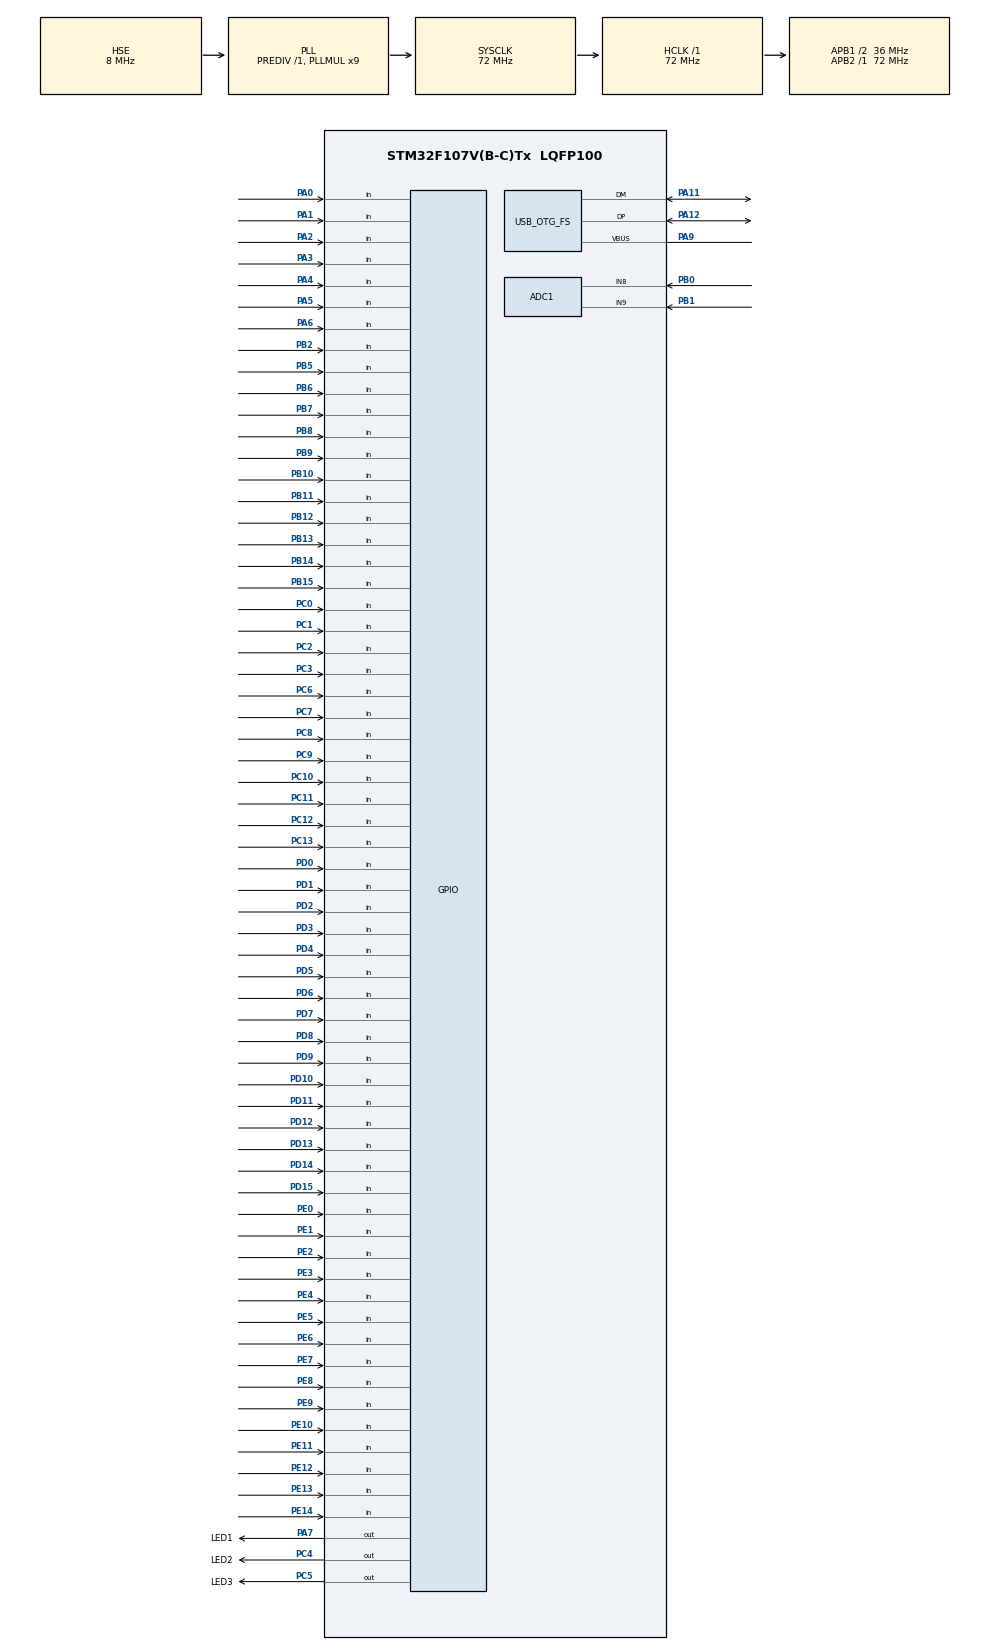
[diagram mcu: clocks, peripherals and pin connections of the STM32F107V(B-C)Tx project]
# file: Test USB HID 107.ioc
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ADC1.Channel-0\#ChannelRegularConversion=ADC_CHANNEL_8
ADC1.Channel-1\#ChannelRegularConversion=ADC_CHANNEL_9
ADC1.ContinuousConvMode=ENABLE
ADC1.NbrOfConversion=2
ADC1.NbrOfConversionFlag=1
ADC1.Rank-0\#ChannelRegularConversion=1
ADC1.Rank-1\#ChannelRegularConversion=2
ADC1.SamplingTime-0\#ChannelRegularConversion=ADC_SAMPLETIME_1CYCLE_5
ADC1.SamplingTime-1\#ChannelRegularConversion=ADC_SAMPLETIME_1CYCLE_5
ADC1.master=1
Mcu.Family=STM32F1
Mcu.Name=STM32F107V(B-C)Tx
Mcu.Package=LQFP100
NVIC.OTG_FS_IRQn=true\:0\:0\:false\:false\:true
NVIC.PriorityGroup=NVIC_PRIORITYGROUP_4
OSC_IN.Mode=HSE-External-Oscillator
OSC_IN.Signal=RCC_OSC_IN
OSC_OUT.Mode=HSE-External-Oscillator
OSC_OUT.Signal=RCC_OSC_OUT
PA0-WKUP.GPIO_Mode=GPIO_MODE_INPUT
PA0-WKUP.GPIO_PuPd=GPIO_PULLUP
PA0-WKUP.Signal=GPIO_Input
PA1.GPIO_PuPd=GPIO_PULLUP
PA1.Signal=GPIO_Input
PA11.Mode=Device_Only
PA11.Signal=USB_OTG_FS_DM
PA12.Mode=Device_Only
PA12.Signal=USB_OTG_FS_DP
PA2.GPIO_Mode=GPIO_MODE_INPUT
PA2.GPIO_PuPd=GPIO_PULLUP
PA2.Signal=GPIO_Input
PA3.GPIO_Mode=GPIO_MODE_INPUT
PA3.GPIO_PuPd=GPIO_PULLUP
PA3.Signal=GPIO_Input
PA4.GPIO_Mode=GPIO_MODE_INPUT
PA4.GPIO_PuPd=GPIO_PULLUP
PA4.Signal=GPIO_Input
PA5.GPIO_Mode=GPIO_MODE_INPUT
PA5.GPIO_PuPd=GPIO_PULLUP
PA5.Signal=GPIO_Input
PA6.GPIO_Mode=GPIO_MODE_INPUT
PA6.GPIO_PuPd=GPIO_PULLUP
PA6.Signal=GPIO_Input
PA7.GPIO_Label=LED1
PA7.GPIO_ModeDefaultOutputPP=GPIO_MODE_OUTPUT_PP
PA7.GPIO_Speed=GPIO_SPEED_FREQ_HIGH
PA7.PinState=GPIO_PIN_RESET
PA7.Signal=GPIO_Output
PA9.Mode=Activate_VBUS
PA9.Signal=USB_OTG_FS_VBUS
PB0.Signal=ADCx_IN8
PB1.Signal=ADCx_IN9
PB10.GPIO_Mode=GPIO_MODE_INPUT
PB10.GPIO_PuPd=GPIO_PULLUP
PB10.Signal=GPIO_Input
PB11.GPIO_Mode=GPIO_MODE_INPUT
PB11.GPIO_PuPd=GPIO_PULLUP
PB11.Signal=GPIO_Input
PB12.GPIO_Mode=GPIO_MODE_INPUT
PB12.GPIO_PuPd=GPIO_PULLUP
PB12.Signal=GPIO_Input
PB13.GPIO_Mode=GPIO_MODE_INPUT
PB13.GPIO_PuPd=GPIO_PULLUP
PB13.Signal=GPIO_Input
PB14.GPIO_Mode=GPIO_MODE_INPUT
PB14.GPIO_PuPd=GPIO_PULLUP
PB14.Signal=GPIO_Input
PB15.GPIO_Mode=GPIO_MODE_INPUT
PB15.GPIO_PuPd=GPIO_PULLUP
PB15.Signal=GPIO_Input
PB2.GPIO_Mode=GPIO_MODE_INPUT
PB2.GPIO_PuPd=GPIO_PULLUP
PB2.Signal=GPIO_Input
PB5.GPIO_Mode=GPIO_MODE_INPUT
PB5.GPIO_PuPd=GPIO_PULLUP
PB5.Signal=GPIO_Input
PB6.GPIO_Mode=GPIO_MODE_INPUT
PB6.GPIO_PuPd=GPIO_PULLUP
PB6.Signal=GPIO_Input
PB7.GPIO_Mode=GPIO_MODE_INPUT
PB7.GPIO_PuPd=GPIO_PULLUP
PB7.Signal=GPIO_Input
PB8.GPIO_Mode=GPIO_MODE_INPUT
PB8.GPIO_PuPd=GPIO_PULLUP
PB8.Signal=GPIO_Input
PB9.GPIO_Mode=GPIO_MODE_INPUT
PB9.GPIO_PuPd=GPIO_PULLUP
PB9.Signal=GPIO_Input
PC0.GPIO_Mode=GPIO_MODE_INPUT
PC0.GPIO_PuPd=GPIO_PULLUP
PC0.Signal=GPIO_Input
PC1.GPIO_Mode=GPIO_MODE_INPUT
PC1.GPIO_PuPd=GPIO_PULLUP
PC1.Signal=GPIO_Input
PC10.GPIO_Mode=GPIO_MODE_INPUT
PC10.GPIO_PuPd=GPIO_PULLUP
PC10.Signal=GPIO_Input
PC11.GPIO_Mode=GPIO_MODE_INPUT
PC11.GPIO_PuPd=GPIO_PULLUP
PC11.Signal=GPIO_Input
PC12.GPIO_Mode=GPIO_MODE_INPUT
PC12.GPIO_PuPd=GPIO_PULLUP
PC12.Signal=GPIO_Input
PC13-TAMPER-RTC.GPIO_Mode=GPIO_MODE_INPUT
PC13-TAMPER-RTC.GPIO_PuPd=GPIO_PULLUP
PC13-TAMPER-RTC.Signal=GPIO_Input
PC2.GPIO_Mode=GPIO_MODE_INPUT
PC2.GPIO_PuPd=GPIO_PULLUP
PC2.Signal=GPIO_Input
PC3.GPIO_Mode=GPIO_MODE_INPUT
PC3.GPIO_PuPd=GPIO_PULLUP
PC3.Signal=GPIO_Input
PC4.GPIO_Label=LED2
PC4.GPIO_ModeDefaultOutputPP=GPIO_MODE_OUTPUT_PP
PC4.GPIO_Speed=GPIO_SPEED_FREQ_HIGH
PC4.PinState=GPIO_PIN_RESET
PC4.Signal=GPIO_Output
PC5.GPIO_Label=LED3
PC5.GPIO_ModeDefaultOutputPP=GPIO_MODE_OUTPUT_PP
PC5.GPIO_Speed=GPIO_SPEED_FREQ_HIGH
PC5.PinState=GPIO_PIN_RESET
PC5.Signal=GPIO_Output
PC6.GPIO_Mode=GPIO_MODE_INPUT
PC6.GPIO_PuPd=GPIO_PULLUP
PC6.Signal=GPIO_Input
PC7.GPIO_Mode=GPIO_MODE_INPUT
PC7.GPIO_PuPd=GPIO_PULLUP
PC7.Signal=GPIO_Input
PC8.GPIO_Mode=GPIO_MODE_INPUT
PC8.GPIO_PuPd=GPIO_PULLUP
PC8.Signal=GPIO_Input
PC9.GPIO_Mode=GPIO_MODE_INPUT
PC9.GPIO_PuPd=GPIO_PULLUP
PC9.Signal=GPIO_Input
PD0.GPIO_Mode=GPIO_MODE_INPUT
PD0.GPIO_PuPd=GPIO_PULLUP
PD0.Signal=GPIO_Input
PD1.GPIO_Mode=GPIO_MODE_INPUT
PD1.GPIO_PuPd=GPIO_PULLUP
PD1.Signal=GPIO_Input
PD10.GPIO_Mode=GPIO_MODE_INPUT
PD10.GPIO_PuPd=GPIO_PULLUP
PD10.Signal=GPIO_Input
PD11.GPIO_Mode=GPIO_MODE_INPUT
PD11.GPIO_PuPd=GPIO_PULLUP
PD11.Signal=GPIO_Input
PD12.GPIO_Mode=GPIO_MODE_INPUT
PD12.GPIO_PuPd=GPIO_PULLUP
PD12.Signal=GPIO_Input
PD13.GPIO_Mode=GPIO_MODE_INPUT
PD13.GPIO_PuPd=GPIO_PULLUP
PD13.Signal=GPIO_Input
PD14.GPIO_Mode=GPIO_MODE_INPUT
PD14.GPIO_PuPd=GPIO_PULLUP
PD14.Signal=GPIO_Input
PD15.GPIO_PuPd=GPIO_PULLUP
PD15.Signal=GPIO_Input
PD2.GPIO_Mode=GPIO_MODE_INPUT
PD2.GPIO_PuPd=GPIO_PULLUP
PD2.Signal=GPIO_Input
PD3.GPIO_Mode=GPIO_MODE_INPUT
PD3.GPIO_PuPd=GPIO_PULLUP
PD3.Signal=GPIO_Input
PD4.GPIO_Mode=GPIO_MODE_INPUT
PD4.GPIO_PuPd=GPIO_PULLUP
PD4.Signal=GPIO_Input
PD5.GPIO_Mode=GPIO_MODE_INPUT
PD5.GPIO_PuPd=GPIO_PULLUP
PD5.Signal=GPIO_Input
PD6.GPIO_Mode=GPIO_MODE_INPUT
PD6.GPIO_PuPd=GPIO_PULLUP
PD6.Signal=GPIO_Input
PD7.GPIO_Mode=GPIO_MODE_INPUT
PD7.GPIO_PuPd=GPIO_PULLUP
PD7.Signal=GPIO_Input
PD8.GPIO_Mode=GPIO_MODE_INPUT
PD8.GPIO_PuPd=GPIO_PULLUP
PD8.Signal=GPIO_Input
PD9.GPIO_Mode=GPIO_MODE_INPUT
PD9.GPIO_PuPd=GPIO_PULLUP
PD9.Signal=GPIO_Input
PE0.GPIO_Mode=GPIO_MODE_INPUT
PE0.GPIO_PuPd=GPIO_PULLUP
PE0.Signal=GPIO_Input
PE1.GPIO_Mode=GPIO_MODE_INPUT
PE1.GPIO_PuPd=GPIO_PULLUP
PE1.Signal=GPIO_Input
PE10.GPIO_Mode=GPIO_MODE_INPUT
PE10.GPIO_PuPd=GPIO_PULLUP
PE10.Signal=GPIO_Input
PE11.GPIO_Mode=GPIO_MODE_INPUT
PE11.GPIO_PuPd=GPIO_PULLUP
PE11.Signal=GPIO_Input
PE12.GPIO_Mode=GPIO_MODE_INPUT
PE12.GPIO_PuPd=GPIO_PULLUP
PE12.Signal=GPIO_Input
PE13.GPIO_Mode=GPIO_MODE_INPUT
PE13.GPIO_PuPd=GPIO_PULLUP
PE13.Signal=GPIO_Input
PE14.GPIO_Mode=GPIO_MODE_INPUT
PE14.GPIO_PuPd=GPIO_PULLUP
PE14.Signal=GPIO_Input
PE2.GPIO_Mode=GPIO_MODE_INPUT
PE2.GPIO_PuPd=GPIO_PULLUP
PE2.Signal=GPIO_Input
PE3.GPIO_Mode=GPIO_MODE_INPUT
PE3.GPIO_PuPd=GPIO_PULLUP
PE3.Signal=GPIO_Input
PE4.GPIO_Mode=GPIO_MODE_INPUT
PE4.GPIO_PuPd=GPIO_PULLUP
PE4.Signal=GPIO_Input
PE5.GPIO_Mode=GPIO_MODE_INPUT
PE5.GPIO_PuPd=GPIO_PULLUP
PE5.Signal=GPIO_Input
PE6.Signal=GPIO_Input
PE7.GPIO_Mode=GPIO_MODE_INPUT
PE7.GPIO_PuPd=GPIO_PULLUP
PE7.Signal=GPIO_Input
PE8.GPIO_Mode=GPIO_MODE_INPUT
PE8.GPIO_PuPd=GPIO_PULLUP
PE8.Signal=GPIO_Input
PE9.GPIO_Mode=GPIO_MODE_INPUT
PE9.GPIO_PuPd=GPIO_PULLUP
PE9.Signal=GPIO_Input
ProjectManager.HeapSize=0x200
ProjectManager.StackSize=0x400
ProjectManager.TargetToolchain=MDK-ARM V5
RCC.ADCPresc=RCC_ADCPCLK2_DIV8
RCC.AHBFreq_Value=72000000
RCC.APB1CLKDivider=RCC_HCLK_DIV2
RCC.APB1Freq_Value=36000000
RCC.APB1TimFreq_Value=72000000
RCC.APB2Freq_Value=72000000
RCC.APB2TimCLKDivider=2
RCC.APB2TimFreq_Value=144000000
RCC.HCLKFreq_Value=72000000
RCC.HSIState=RCC_HSI_ON
RCC.PLLMUL=RCC_PLL_MUL9
RCC.SYSCLKFreq_VALUE=72000000
RCC.SYSCLKSource=RCC_SYSCLKSOURCE_PLLCLK
RCC.USBFreq_Value=48000000
SH.ADCx_IN8.0=ADC1_IN8,IN8
SH.ADCx_IN9.0=ADC1_IN9,IN9
USB_DEVICE.USBD_HandleTypeDef=hUsbDeviceFS
USB_DEVICE.VirtualMode=Hid
USB_DEVICE.VirtualModeFS=Hid_FS
USB_OTG_FS.VirtualMode=Device_Only
VP_SYS_VS_ND.Mode=No_Debug
VP_USB_DEVICE_VS_USB_DEVICE_HID_FS.Mode=HID_FS
board=Test USB HID 107

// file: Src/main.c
/**
  ******************************************************************************
  * File Name          : main.c
  * Description        : Main program body
  ******************************************************************************
  *
  * Copyright (c) 2016 STMicroelectronics International N.V.
  * All rights reserved.
  *
  * Redistribution and use in source and binary forms, with or without
  * modification, are permitted, provided that the following conditions are met:
  *
  * 1. Redistribution of source code must retain the above copyright notice,
  *    this list of conditions and the following disclaimer.
  * 2. Redistributions in binary form must reproduce the above copyright notice,
  *    this list of conditions and the following disclaimer in the documentation
  *    and/or other materials provided with the distribution.
  * 3. Neither the name of STMicroelectronics nor the names of other
  *    contributors to this software may be used to endorse or promote products
  *    derived from this software without specific written permission.
  * 4. This software, including modifications and/or derivative works of this
  *    software, must execute solely and exclusively on microcontroller or
  *    microprocessor devices manufactured by or for STMicroelectronics.
  * 5. Redistribution and use of this software other than as permitted under
  *    this license is void and will automatically terminate your rights under
  *    this license.
  *
  * THIS SOFTWARE IS PROVIDED BY STMICROELECTRONICS AND CONTRIBUTORS "AS IS"
  * AND ANY EXPRESS, IMPLIED OR STATUTORY WARRANTIES, INCLUDING, BUT NOT
  * LIMITED TO, THE IMPLIED WARRANTIES OF MERCHANTABILITY, FITNESS FOR A
  * PARTICULAR PURPOSE AND NON-INFRINGEMENT OF THIRD PARTY INTELLECTUAL PROPERTY
  * RIGHTS ARE DISCLAIMED TO THE FULLEST EXTENT PERMITTED BY LAW. IN NO EVENT
  * SHALL STMICROELECTRONICS OR CONTRIBUTORS BE LIABLE FOR ANY DIRECT, INDIRECT,
  * INCIDENTAL, SPECIAL, EXEMPLARY, OR CONSEQUENTIAL DAMAGES (INCLUDING, BUT NOT
  * LIMITED TO, PROCUREMENT OF SUBSTITUTE GOODS OR SERVICES; LOSS OF USE, DATA,
  * OR PROFITS; OR BUSINESS INTERRUPTION) HOWEVER CAUSED AND ON ANY THEORY OF
  * LIABILITY, WHETHER IN CONTRACT, STRICT LIABILITY, OR TORT (INCLUDING
  * NEGLIGENCE OR OTHERWISE) ARISING IN ANY WAY OUT OF THE USE OF THIS SOFTWARE,
  * EVEN IF ADVISED OF THE POSSIBILITY OF SUCH DAMAGE.
  *
  ******************************************************************************
  */
#include "main.h"
#include "stm32f1xx_hal.h"
#include "usb_device.h"

/* USER CODE BEGIN Includes */
#include "usbd_hid.h" //Add
/* USER CODE END Includes */

ADC_HandleTypeDef hadc1;
DMA_HandleTypeDef hdma_adc1;

/* USER CODE BEGIN PV */
/* Private variables ---------------------------------------------------------*/
__IO uint16_t ADC_value[2] = {0};
/* USER CODE END PV */

void SystemClock_Config(void);
void Error_Handler(void);
static void MX_GPIO_Init(void);
static void MX_DMA_Init(void);
static void MX_ADC1_Init(void);

/* USER CODE BEGIN PFP */
/* Private function prototypes -----------------------------------------------*/
extern USBD_HandleTypeDef hUsbDeviceFS;
/* USER CODE END PFP */

/* USER CODE BEGIN 0 */

/*
 * Keyboard buffer:
 * buf[1]: MOD (2=SHIFT, 1= CTRL,3=?
 * buf[2]: reserved
 * buf[3]..buf[8] - keycodes 1..6
 */

uint8_t buffer[8]= {0,0,0,0,0,0,0,0};//

void keyboard_write(uint8_t char1){
    buffer[2]=char1;
    USBD_HID_SendReport(&hUsbDeviceFS,buffer,8); //sizeof(buffer));
    HAL_Delay(100);
		buffer[0] = 0; buffer[2]=0; USBD_HID_SendReport(&hUsbDeviceFS,buffer,8);
}

void ReadKeyboard (void)
{
	//GPIOD
	if (!HAL_GPIO_ReadPin(GPIOD,GPIO_PIN_15)) { HAL_Delay(10); if (!HAL_GPIO_ReadPin(GPIOD,GPIO_PIN_15)) { while (!HAL_GPIO_ReadPin(GPIOD,GPIO_PIN_15)){} keyboard_write(KEY_J);}}	//J
	if (!HAL_GPIO_ReadPin(GPIOD,GPIO_PIN_14)) { HAL_Delay(10); if (!HAL_GPIO_ReadPin(GPIOD,GPIO_PIN_14)) { while (!HAL_GPIO_ReadPin(GPIOD,GPIO_PIN_14)){} keyboard_write(KEY_K);}}	//K
	if (!HAL_GPIO_ReadPin(GPIOD,GPIO_PIN_13)) { HAL_Delay(10); if (!HAL_GPIO_ReadPin(GPIOD,GPIO_PIN_13)) { while (!HAL_GPIO_ReadPin(GPIOD,GPIO_PIN_13)){} keyboard_write(KEY_L);}}	//L
	if (!HAL_GPIO_ReadPin(GPIOD,GPIO_PIN_12)) { HAL_Delay(10); if (!HAL_GPIO_ReadPin(GPIOD,GPIO_PIN_12)) { while (!HAL_GPIO_ReadPin(GPIOD,GPIO_PIN_12)){} keyboard_write(KEY_F8);}}		// ,
	if (!HAL_GPIO_ReadPin(GPIOD,GPIO_PIN_11)) { HAL_Delay(10); if (!HAL_GPIO_ReadPin(GPIOD,GPIO_PIN_11)) { while (!HAL_GPIO_ReadPin(GPIOD,GPIO_PIN_11)){} keyboard_write(KEY_F9);}}		// =
	if (!HAL_GPIO_ReadPin(GPIOD,GPIO_PIN_10)) { HAL_Delay(10); if (!HAL_GPIO_ReadPin(GPIOD,GPIO_PIN_10)) { while (!HAL_GPIO_ReadPin(GPIOD,GPIO_PIN_10)){} keyboard_write(KEY_F21);}}	//F11 -> F21
	if (!HAL_GPIO_ReadPin(GPIOD,GPIO_PIN_9)) { HAL_Delay(10); if (!HAL_GPIO_ReadPin(GPIOD,GPIO_PIN_9)) { while (!HAL_GPIO_ReadPin(GPIOD,GPIO_PIN_9)){} keyboard_write(KEY_F20);}}			//F10->20
	if (!HAL_GPIO_ReadPin(GPIOD,GPIO_PIN_8)) { HAL_Delay(10); if (!HAL_GPIO_ReadPin(GPIOD,GPIO_PIN_8)) { while (!HAL_GPIO_ReadPin(GPIOD,GPIO_PIN_8)){} keyboard_write(KEY_F4);}}			//^ ???
	if (!HAL_GPIO_ReadPin(GPIOD,GPIO_PIN_7)) { HAL_Delay(10); if (!HAL_GPIO_ReadPin(GPIOD,GPIO_PIN_7)) { while (!HAL_GPIO_ReadPin(GPIOD,GPIO_PIN_7)){} keyboard_write(KEY_G);}}			//G
	if (!HAL_GPIO_ReadPin(GPIOD,GPIO_PIN_6)) { HAL_Delay(10); if (!HAL_GPIO_ReadPin(GPIOD,GPIO_PIN_6)) { while (!HAL_GPIO_ReadPin(GPIOD,GPIO_PIN_6)){} keyboard_write(KEY_H);}}			//H
	if (!HAL_GPIO_ReadPin(GPIOD,GPIO_PIN_5)) { HAL_Delay(10); if (!HAL_GPIO_ReadPin(GPIOD,GPIO_PIN_5)) { while (!HAL_GPIO_ReadPin(GPIOD,GPIO_PIN_5)){} keyboard_write(KEY_U);}}			//U
	if (!HAL_GPIO_ReadPin(GPIOD,GPIO_PIN_4)) { HAL_Delay(10); if (!HAL_GPIO_ReadPin(GPIOD,GPIO_PIN_4)) { while (!HAL_GPIO_ReadPin(GPIOD,GPIO_PIN_4)){} keyboard_write(KEY_I);}}			//I
	if (!HAL_GPIO_ReadPin(GPIOD,GPIO_PIN_3)) { HAL_Delay(10); if (!HAL_GPIO_ReadPin(GPIOD,GPIO_PIN_3)) { while (!HAL_GPIO_ReadPin(GPIOD,GPIO_PIN_3)){} keyboard_write(KEY_O);}}		//O
	if (!HAL_GPIO_ReadPin(GPIOD,GPIO_PIN_2)) { HAL_Delay(10); if (!HAL_GPIO_ReadPin(GPIOD,GPIO_PIN_2)) { while (!HAL_GPIO_ReadPin(GPIOD,GPIO_PIN_2)){} keyboard_write(KEY_P);}}			//P
	if (!HAL_GPIO_ReadPin(GPIOD,GPIO_PIN_1)) { HAL_Delay(10); if (!HAL_GPIO_ReadPin(GPIOD,GPIO_PIN_1)) { while (!HAL_GPIO_ReadPin(GPIOD,GPIO_PIN_1)){} keyboard_write(KEY_F13);}}		//[
	if (!HAL_GPIO_ReadPin(GPIOD,GPIO_PIN_0)) { HAL_Delay(10); if (!HAL_GPIO_ReadPin(GPIOD,GPIO_PIN_0)) { while (!HAL_GPIO_ReadPin(GPIOD,GPIO_PIN_0)){} keyboard_write(KEY_F14);}}		//]
 // GPIOA
 	//if (!HAL_GPIO_ReadPin(GPIOA,GPIO_PIN_7)) { HAL_Delay(10); if (!HAL_GPIO_ReadPin(GPIOA,GPIO_PIN_7)) { while (!HAL_GPIO_ReadPin(GPIOA,GPIO_PIN_7)){} keyboard_write(KEY_G);}}			//LED
	if (!HAL_GPIO_ReadPin(GPIOA,GPIO_PIN_6)) { HAL_Delay(10); if (!HAL_GPIO_ReadPin(GPIOA,GPIO_PIN_6)) { while (!HAL_GPIO_ReadPin(GPIOA,GPIO_PIN_6)){} keyboard_write(KEY_X);}}			//X
	if (!HAL_GPIO_ReadPin(GPIOA,GPIO_PIN_5)) { HAL_Delay(10); if (!HAL_GPIO_ReadPin(GPIOA,GPIO_PIN_5)) { while (!HAL_GPIO_ReadPin(GPIOA,GPIO_PIN_5)){} keyboard_write(KEY_Z);}}			//Z
	if (!HAL_GPIO_ReadPin(GPIOA,GPIO_PIN_4)) { HAL_Delay(10); if (!HAL_GPIO_ReadPin(GPIOA,GPIO_PIN_4)) { while (!HAL_GPIO_ReadPin(GPIOA,GPIO_PIN_4)){} keyboard_write(KEY_HOME);}}			//"
	if (!HAL_GPIO_ReadPin(GPIOA,GPIO_PIN_3)) { HAL_Delay(10); if (!HAL_GPIO_ReadPin(GPIOA,GPIO_PIN_3)) { while (!HAL_GPIO_ReadPin(GPIOA,GPIO_PIN_3)){} keyboard_write(KEY_A);}}		//;
	if (!HAL_GPIO_ReadPin(GPIOA,GPIO_PIN_2)) { HAL_Delay(10); if (!HAL_GPIO_ReadPin(GPIOA,GPIO_PIN_2)) { while (!HAL_GPIO_ReadPin(GPIOA,GPIO_PIN_2)){} keyboard_write(KEY_BACKSPACE);}}			//<--
	if (!HAL_GPIO_ReadPin(GPIOA,GPIO_PIN_1)) { HAL_Delay(10); if (!HAL_GPIO_ReadPin(GPIOA,GPIO_PIN_1)) { while (!HAL_GPIO_ReadPin(GPIOA,GPIO_PIN_1)){} keyboard_write(KEY_KEYPAD_0_INSERT);}}		//0
	if (!HAL_GPIO_ReadPin(GPIOA,GPIO_PIN_0)) { HAL_Delay(10); if (!HAL_GPIO_ReadPin(GPIOA,GPIO_PIN_0)) { while (!HAL_GPIO_ReadPin(GPIOA,GPIO_PIN_0)){} keyboard_write(KEY_KEYPAD_9_PAGEUP);}}		//9
	//GPIOB
	if (!HAL_GPIO_ReadPin(GPIOB,GPIO_PIN_15)) { HAL_Delay(10); if (!HAL_GPIO_ReadPin(GPIOB,GPIO_PIN_15)) { while (!HAL_GPIO_ReadPin(GPIOB,GPIO_PIN_15)){} keyboard_write(KEY_F5);}}	//&
	if (!HAL_GPIO_ReadPin(GPIOB,GPIO_PIN_14)) { HAL_Delay(10); if (!HAL_GPIO_ReadPin(GPIOB,GPIO_PIN_14)) { while (!HAL_GPIO_ReadPin(GPIOB,GPIO_PIN_14)){} keyboard_write(KEY_F7);}}	//(
	if (!HAL_GPIO_ReadPin(GPIOB,GPIO_PIN_13)) { HAL_Delay(10); if (!HAL_GPIO_ReadPin(GPIOB,GPIO_PIN_13)) { while (!HAL_GPIO_ReadPin(GPIOB,GPIO_PIN_13)){} keyboard_write(KEY_F6);}}		//*
	if (!HAL_GPIO_ReadPin(GPIOB,GPIO_PIN_12)) { HAL_Delay(10); if (!HAL_GPIO_ReadPin(GPIOB,GPIO_PIN_12)) { while (!HAL_GPIO_ReadPin(GPIOB,GPIO_PIN_12)){} keyboard_write(KEY_ESCAPE);}}		//!
	if (!HAL_GPIO_ReadPin(GPIOB,GPIO_PIN_11)) { HAL_Delay(10); if (!HAL_GPIO_ReadPin(GPIOB,GPIO_PIN_11)) { while (!HAL_GPIO_ReadPin(GPIOB,GPIO_PIN_11)){} keyboard_write(KEY_F1);}}		//F1
	if (!HAL_GPIO_ReadPin(GPIOB,GPIO_PIN_10)) { HAL_Delay(10); if (!HAL_GPIO_ReadPin(GPIOB,GPIO_PIN_10)) { while (!HAL_GPIO_ReadPin(GPIOB,GPIO_PIN_10)){} keyboard_write(KEY_F2);}}		//F2
	if (!HAL_GPIO_ReadPin(GPIOB,GPIO_PIN_9)) { HAL_Delay(10); if (!HAL_GPIO_ReadPin(GPIOB,GPIO_PIN_9)) { while (!HAL_GPIO_ReadPin(GPIOB,GPIO_PIN_9)){} keyboard_write(KEY_S);}}			//S
	if (!HAL_GPIO_ReadPin(GPIOB,GPIO_PIN_8)) { HAL_Delay(10); if (!HAL_GPIO_ReadPin(GPIOB,GPIO_PIN_8)) { while (!HAL_GPIO_ReadPin(GPIOB,GPIO_PIN_8)){} keyboard_write(KEY_D);}}			//D
	if (!HAL_GPIO_ReadPin(GPIOB,GPIO_PIN_7)) { HAL_Delay(10); if (!HAL_GPIO_ReadPin(GPIOB,GPIO_PIN_7)) { while (!HAL_GPIO_ReadPin(GPIOB,GPIO_PIN_7)){} keyboard_write(KEY_F);}}			//F
	if (!HAL_GPIO_ReadPin(GPIOB,GPIO_PIN_6)) { HAL_Delay(10); if (!HAL_GPIO_ReadPin(GPIOB,GPIO_PIN_6)) { while (!HAL_GPIO_ReadPin(GPIOB,GPIO_PIN_6)){} keyboard_write(KEY_T);}}			//T
	if (!HAL_GPIO_ReadPin(GPIOB,GPIO_PIN_5)) { HAL_Delay(10); if (!HAL_GPIO_ReadPin(GPIOB,GPIO_PIN_5)) { while (!HAL_GPIO_ReadPin(GPIOB,GPIO_PIN_5)){} keyboard_write(KEY_Y);}}			//Y
				// Joytick Button ....
	if (!HAL_GPIO_ReadPin(GPIOB,GPIO_PIN_2)) { HAL_Delay(10); if (!HAL_GPIO_ReadPin(GPIOB,GPIO_PIN_2)) { while (!HAL_GPIO_ReadPin(GPIOB,GPIO_PIN_2)){} keyboard_write(KEY_ENTER);}}			//KEY_ENTER

	//GPIOC
	if (!HAL_GPIO_ReadPin(GPIOC,GPIO_PIN_14)) { HAL_Delay(10); if (!HAL_GPIO_ReadPin(GPIOC,GPIO_PIN_14)) { while (!HAL_GPIO_ReadPin(GPIOC,GPIO_PIN_14)){} keyboard_write(KEY_V);}}		//V
	if (!HAL_GPIO_ReadPin(GPIOC,GPIO_PIN_13)) { HAL_Delay(10); if (!HAL_GPIO_ReadPin(GPIOC,GPIO_PIN_13)) { while (!HAL_GPIO_ReadPin(GPIOC,GPIO_PIN_13)){} keyboard_write(KEY_KEYPAD_4_LEFT_ARROW);}}		//4
	if (!HAL_GPIO_ReadPin(GPIOC,GPIO_PIN_12)) { HAL_Delay(10); if (!HAL_GPIO_ReadPin(GPIOC,GPIO_PIN_12)) { while (!HAL_GPIO_ReadPin(GPIOC,GPIO_PIN_12)){} keyboard_write(KEY_PAGEUP);}}		//{
	if (!HAL_GPIO_ReadPin(GPIOC,GPIO_PIN_11)) { HAL_Delay(10); if (!HAL_GPIO_ReadPin(GPIOC,GPIO_PIN_11)) { while (!HAL_GPIO_ReadPin(GPIOC,GPIO_PIN_11)){} keyboard_write(KEY_PAGEDOWN);}}		//}
	if (!HAL_GPIO_ReadPin(GPIOC,GPIO_PIN_10)) { HAL_Delay(10); if (!HAL_GPIO_ReadPin(GPIOC,GPIO_PIN_10)) { while (!HAL_GPIO_ReadPin(GPIOC,GPIO_PIN_10)){} keyboard_write(KEY_LEFTARROW);}}		//LEFT
	if (!HAL_GPIO_ReadPin(GPIOC,GPIO_PIN_9)) { HAL_Delay(10); if (!HAL_GPIO_ReadPin(GPIOC,GPIO_PIN_9)) { while (!HAL_GPIO_ReadPin(GPIOC,GPIO_PIN_9)){} keyboard_write(KEY_RIGHTARROW);}}	//RIGHT
	if (!HAL_GPIO_ReadPin(GPIOC,GPIO_PIN_8)) { HAL_Delay(10); if (!HAL_GPIO_ReadPin(GPIOC,GPIO_PIN_8)) { while (!HAL_GPIO_ReadPin(GPIOC,GPIO_PIN_8)){} keyboard_write(KEY_UPARROW);}}			//UP
	if (!HAL_GPIO_ReadPin(GPIOC,GPIO_PIN_7)) { HAL_Delay(10); if (!HAL_GPIO_ReadPin(GPIOC,GPIO_PIN_7)) { while (!HAL_GPIO_ReadPin(GPIOC,GPIO_PIN_7)){} keyboard_write(KEY_DOWNARROW);}}			//DOWN
	if (!HAL_GPIO_ReadPin(GPIOC,GPIO_PIN_6)) { HAL_Delay(10); if (!HAL_GPIO_ReadPin(GPIOC,GPIO_PIN_6)) { while (!HAL_GPIO_ReadPin(GPIOC,GPIO_PIN_6)){} keyboard_write(KEY_C);}}		//C CENTER
	if (!HAL_GPIO_ReadPin(GPIOC,GPIO_PIN_3)) { HAL_Delay(10); if (!HAL_GPIO_ReadPin(GPIOC,GPIO_PIN_3)) { while (!HAL_GPIO_ReadPin(GPIOC,GPIO_PIN_3)){} keyboard_write(KEY_KEYPAD_8_UP_ARROW);}}		//8
	if (!HAL_GPIO_ReadPin(GPIOC,GPIO_PIN_2)) { HAL_Delay(10); if (!HAL_GPIO_ReadPin(GPIOC,GPIO_PIN_2)) { while (!HAL_GPIO_ReadPin(GPIOC,GPIO_PIN_2)){} keyboard_write(KEY_KEYPAD_7_HOME);}}		//7
	if (!HAL_GPIO_ReadPin(GPIOC,GPIO_PIN_1)) { HAL_Delay(10); if (!HAL_GPIO_ReadPin(GPIOC,GPIO_PIN_1)) { while (!HAL_GPIO_ReadPin(GPIOC,GPIO_PIN_1)){} keyboard_write(KEY_KEYPAD_6_RIGHT_ARROW);}}		//6
	if (!HAL_GPIO_ReadPin(GPIOC,GPIO_PIN_0)) { HAL_Delay(10); if (!HAL_GPIO_ReadPin(GPIOC,GPIO_PIN_0)) { while (!HAL_GPIO_ReadPin(GPIOC,GPIO_PIN_0)){} keyboard_write(KEY_KEYPAD_5);}}		//5
	//GPIOE
	if (!HAL_GPIO_ReadPin(GPIOE,GPIO_PIN_14)) { HAL_Delay(10); if (!HAL_GPIO_ReadPin(GPIOE,GPIO_PIN_14)) { while (!HAL_GPIO_ReadPin(GPIOE,GPIO_PIN_14)){} keyboard_write(KEY_F3);}}	 // F3
	if (!HAL_GPIO_ReadPin(GPIOE,GPIO_PIN_13)) { HAL_Delay(10); if (!HAL_GPIO_ReadPin(GPIOE,GPIO_PIN_13)) { while (!HAL_GPIO_ReadPin(GPIOE,GPIO_PIN_13)){} keyboard_write(KEY_F12 );}}		// <	,
	if (!HAL_GPIO_ReadPin(GPIOE,GPIO_PIN_12)) { HAL_Delay(10); if (!HAL_GPIO_ReadPin(GPIOE,GPIO_PIN_12)) { while (!HAL_GPIO_ReadPin(GPIOE,GPIO_PIN_12)){} keyboard_write(KEY_END1);}}		// > .
	if (!HAL_GPIO_ReadPin(GPIOE,GPIO_PIN_11)) { HAL_Delay(10); if (!HAL_GPIO_ReadPin(GPIOE,GPIO_PIN_11)) { while (!HAL_GPIO_ReadPin(GPIOE,GPIO_PIN_11)){} keyboard_write(KEY_DELETE);}}		// /
	if (!HAL_GPIO_ReadPin(GPIOE,GPIO_PIN_10)) { HAL_Delay(10); if (!HAL_GPIO_ReadPin(GPIOE,GPIO_PIN_10)) { while (!HAL_GPIO_ReadPin(GPIOE,GPIO_PIN_10)){} keyboard_write(KEY_INSERT);}}		// ? => `
	if (!HAL_GPIO_ReadPin(GPIOE,GPIO_PIN_9)) { HAL_Delay(10); if (!HAL_GPIO_ReadPin(GPIOE,GPIO_PIN_9)) { while (!HAL_GPIO_ReadPin(GPIOE,GPIO_PIN_9)){} keyboard_write(KEY_B);}}			//B
	if (!HAL_GPIO_ReadPin(GPIOE,GPIO_PIN_8)) { HAL_Delay(10); if (!HAL_GPIO_ReadPin(GPIOE,GPIO_PIN_8)) { while (!HAL_GPIO_ReadPin(GPIOE,GPIO_PIN_8)){} keyboard_write(KEY_N);}}			//N
	if (!HAL_GPIO_ReadPin(GPIOE,GPIO_PIN_7)) { HAL_Delay(10); if (!HAL_GPIO_ReadPin(GPIOE,GPIO_PIN_7)) { while (!HAL_GPIO_ReadPin(GPIOE,GPIO_PIN_7)){} keyboard_write(KEY_M);}}			//M
	if (!HAL_GPIO_ReadPin(GPIOE,GPIO_PIN_6)) { HAL_Delay(10); if (!HAL_GPIO_ReadPin(GPIOE,GPIO_PIN_6)) { while (!HAL_GPIO_ReadPin(GPIOE,GPIO_PIN_6)){} keyboard_write(KEY_KEYPAD_3_PAGEDN);}}			//3
	if (!HAL_GPIO_ReadPin(GPIOE,GPIO_PIN_5)) { HAL_Delay(10); if (!HAL_GPIO_ReadPin(GPIOE,GPIO_PIN_5)) { while (!HAL_GPIO_ReadPin(GPIOE,GPIO_PIN_5)){} keyboard_write(KEY_KEYPAD_2_DOWN_ARROW);}}			//2
	if (!HAL_GPIO_ReadPin(GPIOE,GPIO_PIN_4)) { HAL_Delay(10); if (!HAL_GPIO_ReadPin(GPIOE,GPIO_PIN_4)) { while (!HAL_GPIO_ReadPin(GPIOE,GPIO_PIN_4)){} keyboard_write(KEY_KEYPAD_1_END);}}			//1
	if (!HAL_GPIO_ReadPin(GPIOE,GPIO_PIN_3)) { HAL_Delay(10); if (!HAL_GPIO_ReadPin(GPIOE,GPIO_PIN_3)) { while (!HAL_GPIO_ReadPin(GPIOE,GPIO_PIN_3)){} keyboard_write(KEY_W);}}		//W
	if (!HAL_GPIO_ReadPin(GPIOE,GPIO_PIN_2)) { HAL_Delay(10); if (!HAL_GPIO_ReadPin(GPIOE,GPIO_PIN_2)) { while (!HAL_GPIO_ReadPin(GPIOE,GPIO_PIN_2)){} keyboard_write(KEY_Q);}}			//Q
	if (!HAL_GPIO_ReadPin(GPIOE,GPIO_PIN_1)) { HAL_Delay(10); if (!HAL_GPIO_ReadPin(GPIOE,GPIO_PIN_1)) { while (!HAL_GPIO_ReadPin(GPIOE,GPIO_PIN_1)){} keyboard_write(KEY_E);}}		//E
	if (!HAL_GPIO_ReadPin(GPIOE,GPIO_PIN_0)) { HAL_Delay(10); if (!HAL_GPIO_ReadPin(GPIOE,GPIO_PIN_0)) { while (!HAL_GPIO_ReadPin(GPIOE,GPIO_PIN_0)){} keyboard_write(KEY_R);}}		//R
}
void ReadAdc (void)
{
	//if (!HAL_GPIO_ReadPin(GPIOE,GPIO_PIN_0)) { HAL_Delay(10); if (!HAL_GPIO_ReadPin(GPIOE,GPIO_PIN_0)) { while (!HAL_GPIO_ReadPin(GPIOE,GPIO_PIN_0)){} keyboard_write(KEY_R);}}		//R
	if (ADC_value[0] > 4000 ) { HAL_Delay(100);  keyboard_write(KEY_F18);} // Phai
	if (ADC_value[0] < 100 ) { HAL_Delay(100);   keyboard_write(KEY_F17);} // Trai
	if (ADC_value[1] > 4000 ) { HAL_Delay(100);  keyboard_write(KEY_F15);} // Up
	if (ADC_value[1] < 100 ) { HAL_Delay(100);   keyboard_write(KEY_F16);} // Down
}
/* USER CODE END 0 */
uint8_t item = 4;
int main(void)
{

  /* MCU Configuration----------------------------------------------------------*/

  /* Reset of all peripherals, Initializes the Flash interface and the Systick. */
  HAL_Init();

  /* Configure the system clock */
  SystemClock_Config();

  /* Initialize all configured peripherals */
  MX_GPIO_Init();
  MX_USB_DEVICE_Init();
	MX_DMA_Init();
  MX_ADC1_Init();

  /* USER CODE BEGIN 2 */
	//HAL_Delay(4000);
	HAL_ADC_Start_DMA(&hadc1,(uint32_t*)&ADC_value,2); //???

	//TestKey();
  /* USER CODE END 2 */

  /* Infinite loop */
  while (1)
  {
	 ReadKeyboard();
	 ReadAdc();
  }

}
/** System Clock Configuration
*/
void SystemClock_Config(void)
{

  RCC_OscInitTypeDef RCC_OscInitStruct;
  RCC_ClkInitTypeDef RCC_ClkInitStruct;
  RCC_PeriphCLKInitTypeDef PeriphClkInit;

    /**Initializes the CPU, AHB and APB busses clocks
    */
  RCC_OscInitStruct.OscillatorType = RCC_OSCILLATORTYPE_HSE;
  RCC_OscInitStruct.HSEState = RCC_HSE_ON;
  RCC_OscInitStruct.HSEPredivValue = RCC_HSE_PREDIV_DIV1;
  RCC_OscInitStruct.HSIState = RCC_HSI_ON;
  RCC_OscInitStruct.Prediv1Source = RCC_PREDIV1_SOURCE_HSE;
  RCC_OscInitStruct.PLL.PLLState = RCC_PLL_ON;
  RCC_OscInitStruct.PLL.PLLSource = RCC_PLLSOURCE_HSE;
  RCC_OscInitStruct.PLL.PLLMUL = RCC_PLL_MUL9;
  RCC_OscInitStruct.PLL2.PLL2State = RCC_PLL_NONE;
  if (HAL_RCC_OscConfig(&RCC_OscInitStruct) != HAL_OK)
  {
    Error_Handler();
  }

    /**Initializes the CPU, AHB and APB busses clocks
    */
  RCC_ClkInitStruct.ClockType = RCC_CLOCKTYPE_HCLK|RCC_CLOCKTYPE_SYSCLK
                              |RCC_CLOCKTYPE_PCLK1|RCC_CLOCKTYPE_PCLK2;
  RCC_ClkInitStruct.SYSCLKSource = RCC_SYSCLKSOURCE_PLLCLK;
  RCC_ClkInitStruct.AHBCLKDivider = RCC_SYSCLK_DIV1;
  RCC_ClkInitStruct.APB1CLKDivider = RCC_HCLK_DIV2;
  RCC_ClkInitStruct.APB2CLKDivider = RCC_HCLK_DIV1;

  if (HAL_RCC_ClockConfig(&RCC_ClkInitStruct, FLASH_LATENCY_2) != HAL_OK)
  {
    Error_Handler();
  }

  PeriphClkInit.PeriphClockSelection = RCC_PERIPHCLK_ADC|RCC_PERIPHCLK_USB;
  PeriphClkInit.AdcClockSelection = RCC_ADCPCLK2_DIV8;
  PeriphClkInit.UsbClockSelection = RCC_USBCLKSOURCE_PLL_DIV3;
  if (HAL_RCCEx_PeriphCLKConfig(&PeriphClkInit) != HAL_OK)
  {
    Error_Handler();
  }

    /**Configure the Systick interrupt time
    */
  HAL_SYSTICK_Config(HAL_RCC_GetHCLKFreq()/1000);

    /**Configure the Systick
    */
  HAL_SYSTICK_CLKSourceConfig(SYSTICK_CLKSOURCE_HCLK);

    /**Configure the Systick interrupt time
    */
  __HAL_RCC_PLLI2S_ENABLE();

  /* SysTick_IRQn interrupt configuration */
  HAL_NVIC_SetPriority(SysTick_IRQn, 0, 0);
}

/* ADC1 init function */
static void MX_ADC1_Init(void)
{

  ADC_ChannelConfTypeDef sConfig;

    /**Common config
    */
  hadc1.Instance = ADC1;
  hadc1.Init.ScanConvMode = ADC_SCAN_ENABLE;
  hadc1.Init.ContinuousConvMode = ENABLE;
  hadc1.Init.DiscontinuousConvMode = DISABLE;
  hadc1.Init.ExternalTrigConv = ADC_SOFTWARE_START;
  hadc1.Init.DataAlign = ADC_DATAALIGN_RIGHT;
  hadc1.Init.NbrOfConversion = 2;
	//
  if (HAL_ADC_Init(&hadc1) != HAL_OK)
  {
    Error_Handler();
  }

    /**Configure Regular Channel
    */
  sConfig.Channel = ADC_CHANNEL_8;
  sConfig.Rank = 1;
  sConfig.SamplingTime = ADC_SAMPLETIME_1CYCLE_5;
  if (HAL_ADC_ConfigChannel(&hadc1, &sConfig) != HAL_OK)
  {
    Error_Handler();
  }

    /**Configure Regular Channel
    */
  sConfig.Channel = ADC_CHANNEL_9;
  sConfig.Rank = 2;
  if (HAL_ADC_ConfigChannel(&hadc1, &sConfig) != HAL_OK)
  {
    Error_Handler();
  }

}
static void MX_DMA_Init(void)
{
  /* DMA controller clock enable */
  __HAL_RCC_DMA1_CLK_ENABLE();

  /* DMA interrupt init */
  /* DMA1_Channel1_IRQn interrupt configuration */
  HAL_NVIC_SetPriority(DMA1_Channel1_IRQn, 0, 0);
  HAL_NVIC_EnableIRQ(DMA1_Channel1_IRQn);

}
/** Configure pins as
        * Analog
        * Input
        * Output
        * EVENT_OUT
        * EXTI
*/
static void MX_GPIO_Init(void)
{

  GPIO_InitTypeDef GPIO_InitStruct;

  /* GPIO Ports Clock Enable */
  __HAL_RCC_GPIOE_CLK_ENABLE();
  __HAL_RCC_GPIOC_CLK_ENABLE();
  __HAL_RCC_GPIOA_CLK_ENABLE();
  __HAL_RCC_GPIOB_CLK_ENABLE();
  __HAL_RCC_GPIOD_CLK_ENABLE();

  /*Configure GPIO pins : PE2 PE3 PE4 PE5
                           PE7 PE8 PE9 PE10
                           PE11 PE12 PE13 PE14
                           PE0 PE1 */
  GPIO_InitStruct.Pin = GPIO_PIN_2|GPIO_PIN_3|GPIO_PIN_4|GPIO_PIN_5|GPIO_PIN_6
                          |GPIO_PIN_7|GPIO_PIN_8|GPIO_PIN_9|GPIO_PIN_10
                          |GPIO_PIN_11|GPIO_PIN_12|GPIO_PIN_13|GPIO_PIN_14
                          |GPIO_PIN_0|GPIO_PIN_1;
  GPIO_InitStruct.Mode = GPIO_MODE_INPUT;
  GPIO_InitStruct.Pull = GPIO_PULLUP;
  HAL_GPIO_Init(GPIOE, &GPIO_InitStruct);

  /*Configure GPIO pins : PC13 PC0 PC1 PC2
                           PC3 PC6 PC7 PC8
                           PC9 PC10 PC11 PC12 */
  GPIO_InitStruct.Pin = GPIO_PIN_13|GPIO_PIN_0|GPIO_PIN_1|GPIO_PIN_2
                          |GPIO_PIN_3|GPIO_PIN_6|GPIO_PIN_7|GPIO_PIN_8
                          |GPIO_PIN_9|GPIO_PIN_10|GPIO_PIN_11|GPIO_PIN_12|GPIO_PIN_14;
  GPIO_InitStruct.Mode = GPIO_MODE_INPUT;
  GPIO_InitStruct.Pull = GPIO_PULLUP;
  HAL_GPIO_Init(GPIOC, &GPIO_InitStruct);

  /*Configure GPIO pins : PA0 PA1 PA2 PA3
                           PA4 PA5 PA6 */
  GPIO_InitStruct.Pin = GPIO_PIN_0|GPIO_PIN_1|GPIO_PIN_2|GPIO_PIN_3
                          |GPIO_PIN_4|GPIO_PIN_5|GPIO_PIN_6;
  GPIO_InitStruct.Mode = GPIO_MODE_INPUT;
  GPIO_InitStruct.Pull = GPIO_PULLUP;
  HAL_GPIO_Init(GPIOA, &GPIO_InitStruct);

  /*Configure GPIO pin : LED1_Pin */
  GPIO_InitStruct.Pin = LED1_Pin;
  GPIO_InitStruct.Mode = GPIO_MODE_OUTPUT_PP;
  GPIO_InitStruct.Speed = GPIO_SPEED_FREQ_HIGH;
  HAL_GPIO_Init(LED1_GPIO_Port, &GPIO_InitStruct);

  /*Configure GPIO pins : LED2_Pin LED3_Pin */
  GPIO_InitStruct.Pin = LED2_Pin|LED3_Pin;
  GPIO_InitStruct.Mode = GPIO_MODE_OUTPUT_PP;
  GPIO_InitStruct.Speed = GPIO_SPEED_FREQ_HIGH;
  HAL_GPIO_Init(GPIOC, &GPIO_InitStruct);

  /*Configure GPIO pins : PB2 PB10 PB11 PB12
                           PB13 PB14 PB15 PB5
                           PB6 PB7 PB8 PB9 */
  GPIO_InitStruct.Pin = GPIO_PIN_2|GPIO_PIN_10|GPIO_PIN_11|GPIO_PIN_12
                          |GPIO_PIN_13|GPIO_PIN_14|GPIO_PIN_15|GPIO_PIN_5
                          |GPIO_PIN_6|GPIO_PIN_7|GPIO_PIN_8|GPIO_PIN_9;
  GPIO_InitStruct.Mode = GPIO_MODE_INPUT;
  GPIO_InitStruct.Pull = GPIO_PULLUP;
  HAL_GPIO_Init(GPIOB, &GPIO_InitStruct);

  /*Configure GPIO pins : PD8 PD9 PD10 PD11
                           PD12 PD13 PD14 PD15
                           PD0 PD1 PD2 PD3
                           PD4 PD5 PD6 PD7 */
  GPIO_InitStruct.Pin = GPIO_PIN_8|GPIO_PIN_9|GPIO_PIN_10|GPIO_PIN_11
                          |GPIO_PIN_12|GPIO_PIN_13|GPIO_PIN_14|GPIO_PIN_15
                          |GPIO_PIN_0|GPIO_PIN_1|GPIO_PIN_2|GPIO_PIN_3
                          |GPIO_PIN_4|GPIO_PIN_5|GPIO_PIN_6|GPIO_PIN_7;
  GPIO_InitStruct.Mode = GPIO_MODE_INPUT;
  GPIO_InitStruct.Pull = GPIO_PULLUP;
  HAL_GPIO_Init(GPIOD, &GPIO_InitStruct);

  /*Configure GPIO pin Output Level */
  HAL_GPIO_WritePin(GPIOA, LED1_Pin, GPIO_PIN_SET); //A7

  /*Configure GPIO pin Output Level */
  HAL_GPIO_WritePin(GPIOC, LED2_Pin|LED3_Pin, GPIO_PIN_SET); //C4+C5

}

void Error_Handler(void)
{
  while(1)
  {
  }
}

/************************ (C) COPYRIGHT STMicroelectronics *****END OF FILE****/
